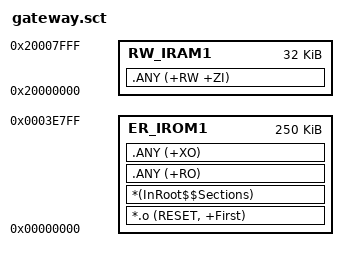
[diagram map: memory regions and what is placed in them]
; *************************************************************
; *** Scatter-Loading Description File for Gateway (no BLE) ***
; *************************************************************

LR_IROM1 0x00000000 0x0003E800  {
  ER_IROM1 0x00000000 0x0003E800  {
    *.o (RESET, +First)
    *(InRoot$$Sections)
    .ANY (+RO)
    .ANY (+XO)
  }

  RW_IRAM1 0x20000000 0x00008000  {
    .ANY (+RW +ZI)
  }
}
